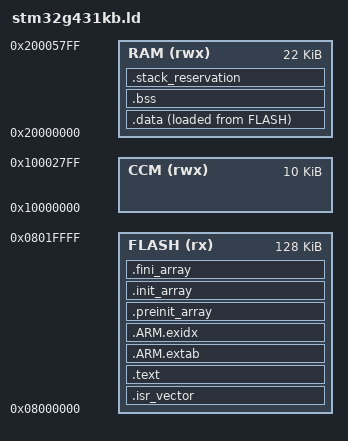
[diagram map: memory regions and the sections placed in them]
/* STM32G431KB: reserve DMA-accessible SRAM separately from the 10 KiB CCM bank. */
ENTRY(Reset_Handler)
MEMORY
{
  FLASH (rx) : ORIGIN = 0x08000000, LENGTH = 128K
  RAM (rwx) : ORIGIN = 0x20000000, LENGTH = 22K
  CCM (rwx) : ORIGIN = 0x10000000, LENGTH = 10K
}
_estack = ORIGIN(RAM) + LENGTH(RAM);
_Min_Stack_Size = 4K;
SECTIONS
{
  .isr_vector : { KEEP(*(.isr_vector)) } > FLASH
  .text :
  {
    *(.text .text.*)
    *(.rodata .rodata.*)
    KEEP(*(.init))
    KEEP(*(.fini))
    . = ALIGN(4);
  } > FLASH
  .ARM.extab : { *(.ARM.extab* .gnu.linkonce.armextab.*) } > FLASH
  .ARM.exidx :
  {
    __exidx_start = .;
    *(.ARM.exidx*)
    __exidx_end = .;
  } > FLASH
  .preinit_array (READONLY) :
  {
    PROVIDE_HIDDEN(__preinit_array_start = .);
    KEEP(*(.preinit_array*))
    PROVIDE_HIDDEN(__preinit_array_end = .);
  } > FLASH
  .init_array (READONLY) :
  {
    PROVIDE_HIDDEN(__init_array_start = .);
    KEEP(*(SORT(.init_array.*)))
    KEEP(*(.init_array))
    PROVIDE_HIDDEN(__init_array_end = .);
  } > FLASH
  .fini_array (READONLY) :
  {
    PROVIDE_HIDDEN(__fini_array_start = .);
    KEEP(*(SORT(.fini_array.*)))
    KEEP(*(.fini_array))
    PROVIDE_HIDDEN(__fini_array_end = .);
  } > FLASH
  _sidata = LOADADDR(.data);
  .data :
  {
    . = ALIGN(4);
    _sdata = .;
    *(.data .data.*)
    . = ALIGN(4);
    _edata = .;
  } > RAM AT> FLASH
  .bss (NOLOAD) :
  {
    . = ALIGN(4);
    _sbss = .;
    __bss_start__ = .;
    *(.bss .bss.* COMMON)
    . = ALIGN(4);
    _ebss = .;
    __bss_end__ = .;
  } > RAM
  .stack_reservation (NOLOAD) :
  {
    . = ALIGN(8);
    end = .;
    _end = .;
    . += _Min_Stack_Size;
  } > RAM
  ASSERT(_ebss <= _estack - _Min_Stack_Size, "SRAM does not leave 4 KiB for stack")
  /DISCARD/ : { *(.note.GNU-stack) }
}
